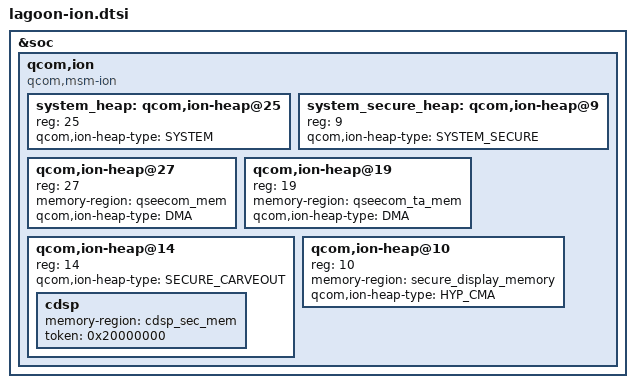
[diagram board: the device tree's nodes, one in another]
&soc {
	qcom,ion {
		compatible = "qcom,msm-ion";
		#address-cells = <1>;
		#size-cells = <0>;

		system_heap: qcom,ion-heap@25 {
			reg = <25>;
			qcom,ion-heap-type = "SYSTEM";
		};

		system_secure_heap: qcom,ion-heap@9 {
			reg = <9>;
			qcom,ion-heap-type = "SYSTEM_SECURE";
		};

		qcom,ion-heap@27 { /* QSEECOM HEAP */
			reg = <27>;
			memory-region = <&qseecom_mem>;
			qcom,ion-heap-type = "DMA";
		};

		qcom,ion-heap@19 { /* QSEECOM TA HEAP */
			reg = <19>;
			memory-region = <&qseecom_ta_mem>;
			qcom,ion-heap-type = "DMA";
		};

		qcom,ion-heap@14 { /* SECURE CARVEOUT HEAP */
			reg = <14>;
			qcom,ion-heap-type = "SECURE_CARVEOUT";
			cdsp {
				memory-region = <&cdsp_sec_mem>;
				token = <0x20000000>;
			};
		};

		qcom,ion-heap@10 { /* SECURE DISPLAY HEAP */
			reg = <10>;
			memory-region = <&secure_display_memory>;
			qcom,ion-heap-type = "HYP_CMA";
		};
	};
};
